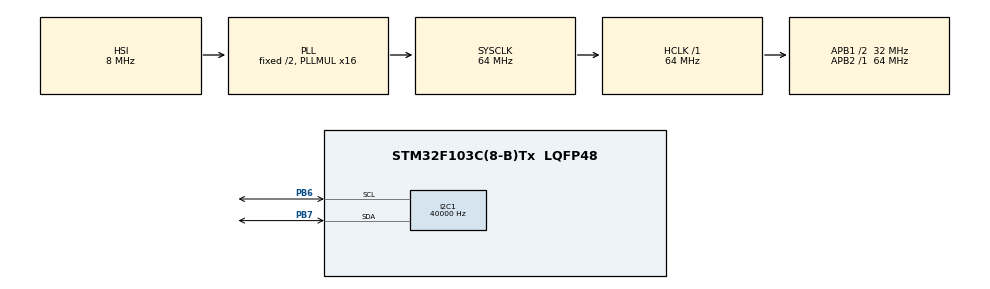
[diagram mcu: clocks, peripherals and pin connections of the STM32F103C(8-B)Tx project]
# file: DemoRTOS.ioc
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FREERTOS.Tasks01=defaultTask,24,256,StartDefaultTask,Default,NULL,Dynamic,NULL,NULL
FREERTOS.configUSE_NEWLIB_REENTRANT=1
I2C1.ClockSpeed=40000
I2C1.I2C_Mode=I2C_Fast
Mcu.Family=STM32F1
Mcu.Name=STM32F103C(8-B)Tx
Mcu.Package=LQFP48
NVIC.PriorityGroup=NVIC_PRIORITYGROUP_4
PB6.Mode=I2C
PB6.Signal=I2C1_SCL
PB7.Mode=I2C
PB7.Signal=I2C1_SDA
ProjectManager.HeapSize=0x200
ProjectManager.StackSize=0x400
ProjectManager.TargetToolchain=STM32CubeIDE
RCC.AHBFreq_Value=64000000
RCC.APB1CLKDivider=RCC_HCLK_DIV2
RCC.APB1Freq_Value=32000000
RCC.APB1TimFreq_Value=64000000
RCC.APB2Freq_Value=64000000
RCC.APB2TimFreq_Value=64000000
RCC.HCLKFreq_Value=64000000
RCC.PLLMUL=RCC_PLL_MUL16
RCC.SYSCLKFreq_VALUE=64000000
RCC.SYSCLKSource=RCC_SYSCLKSOURCE_PLLCLK
RCC.USBFreq_Value=64000000
VP_FREERTOS_VS_CMSIS_V2.Mode=CMSIS_V2
board=custom

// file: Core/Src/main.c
/* USER CODE BEGIN Header */
/**
 ******************************************************************************
 * @file           : main.c
 * @brief          : Main program body
 ******************************************************************************
 * @attention
 *
 * Copyright (c) 2023 STMicroelectronics.
 * All rights reserved.
 *
 * This software is licensed under terms that can be found in the LICENSE file
 * in the root directory of this software component.
 * If no LICENSE file comes with this software, it is provided AS-IS.
 *
 ******************************************************************************
 */
/* USER CODE END Header */
#include "main.h"
#include "cmsis_os.h"
#include "ssd1306.h"

I2C_HandleTypeDef hi2c1;

/* Definitions for defaultTask */
osThreadId_t defaultTaskHandle;
const osThreadAttr_t defaultTask_attributes = { .name = "defaultTask",
		.stack_size = 256 * 4, .priority = (osPriority_t) osPriorityNormal, };

void SystemClock_Config(void);
static void MX_GPIO_Init(void);
static void MX_I2C1_Init(void);
void StartDefaultTask(void *argument);

int main(void) {

	/* MCU Configuration--------------------------------------------------------*/

	/* Reset of all peripherals, Initializes the Flash interface and the Systick. */
	HAL_Init();

	/* Configure the system clock */
	SystemClock_Config();

	/* Initialize all configured peripherals */
	MX_GPIO_Init();
	MX_I2C1_Init();
	ssd1306_Init();

	/* Init scheduler */
	osKernelInitialize();

	/* Create the thread(s) */
	/* creation of defaultTask */
	defaultTaskHandle = osThreadNew(StartDefaultTask, NULL,
			&defaultTask_attributes);

	/* Start scheduler */
	osKernelStart();

	/* We should never get here as control is now taken by the scheduler */
	/* Infinite loop */
	while (1) {

	}
}

void SystemClock_Config(void) {
	RCC_OscInitTypeDef RCC_OscInitStruct = { 0 };
	RCC_ClkInitTypeDef RCC_ClkInitStruct = { 0 };

	/** Initializes the RCC Oscillators according to the specified parameters
	 * in the RCC_OscInitTypeDef structure.
	 */
	RCC_OscInitStruct.OscillatorType = RCC_OSCILLATORTYPE_HSI;
	RCC_OscInitStruct.HSIState = RCC_HSI_ON;
	RCC_OscInitStruct.HSICalibrationValue = RCC_HSICALIBRATION_DEFAULT;
	RCC_OscInitStruct.PLL.PLLState = RCC_PLL_ON;
	RCC_OscInitStruct.PLL.PLLSource = RCC_PLLSOURCE_HSI_DIV2;
	RCC_OscInitStruct.PLL.PLLMUL = RCC_PLL_MUL16;
	if (HAL_RCC_OscConfig(&RCC_OscInitStruct) != HAL_OK) {
		Error_Handler();
	}

	/** Initializes the CPU, AHB and APB buses clocks
	 */
	RCC_ClkInitStruct.ClockType = RCC_CLOCKTYPE_HCLK | RCC_CLOCKTYPE_SYSCLK
			| RCC_CLOCKTYPE_PCLK1 | RCC_CLOCKTYPE_PCLK2;
	RCC_ClkInitStruct.SYSCLKSource = RCC_SYSCLKSOURCE_PLLCLK;
	RCC_ClkInitStruct.AHBCLKDivider = RCC_SYSCLK_DIV1;
	RCC_ClkInitStruct.APB1CLKDivider = RCC_HCLK_DIV2;
	RCC_ClkInitStruct.APB2CLKDivider = RCC_HCLK_DIV1;

	if (HAL_RCC_ClockConfig(&RCC_ClkInitStruct, FLASH_LATENCY_2) != HAL_OK) {
		Error_Handler();
	}
}

static void MX_I2C1_Init(void) {

	hi2c1.Instance = I2C1;
	hi2c1.Init.ClockSpeed = 40000;
	hi2c1.Init.DutyCycle = I2C_DUTYCYCLE_2;
	hi2c1.Init.OwnAddress1 = 0;
	hi2c1.Init.AddressingMode = I2C_ADDRESSINGMODE_7BIT;
	hi2c1.Init.DualAddressMode = I2C_DUALADDRESS_DISABLE;
	hi2c1.Init.OwnAddress2 = 0;
	hi2c1.Init.GeneralCallMode = I2C_GENERALCALL_DISABLE;
	hi2c1.Init.NoStretchMode = I2C_NOSTRETCH_DISABLE;
	if (HAL_I2C_Init(&hi2c1) != HAL_OK) {
		Error_Handler();
	}

}

static void MX_GPIO_Init(void) {

	/* GPIO Ports Clock Enable */
	__HAL_RCC_GPIOB_CLK_ENABLE();

}

void StartDefaultTask(void *argument) {
	/* USER CODE BEGIN 5 */
	/* Infinite loop */
	int status = 0;
	for (;;) {
		ssd1306_Fill(Black);
		ssd1306_SetCursor(1, 10);
		ssd1306_WriteString("Digi", Font_16x26, White);
		ssd1306_SetCursor(45, 35);
		ssd1306_WriteString("Spark", Font_16x26, White);
		ssd1306_UpdateScreen();
		osDelay(1000);
	}
	/* USER CODE END 5 */
}

void Error_Handler(void) {
	__disable_irq();
	while (1) {
	}
}
